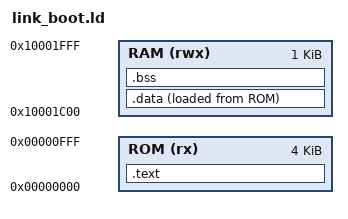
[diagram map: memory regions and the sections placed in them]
/* Linker script bootloader (skenario B): kode di ROM, data dan stack di
 * 1 KB teratas RAM agar 7 KB pertama RAM bebas untuk program yang diunggah. */

OUTPUT_ARCH(riscv)
ENTRY(_start)

MEMORY
{
    ROM (rx)  : ORIGIN = 0x00000000, LENGTH = 4K
    RAM (rwx) : ORIGIN = 0x10001C00, LENGTH = 1K
}

SECTIONS
{
    .text : {
        KEEP(*(.text.start))
        *(.text .text.*)
        *(.rodata .rodata.* .srodata .srodata.*)
        . = ALIGN(4);
    } > ROM

    .data : {
        __data_start = .;
        *(.data .data.* .sdata .sdata.*)
        . = ALIGN(4);
        __data_end = .;
    } > RAM AT > ROM
    __data_load = LOADADDR(.data);

    .bss (NOLOAD) : {
        __bss_start = .;
        *(.bss .bss.* .sbss .sbss.* COMMON)
        . = ALIGN(4);
        __bss_end = .;
    } > RAM

    __stack_top = ORIGIN(RAM) + LENGTH(RAM);

    /DISCARD/ : { *(.comment) *(.riscv.attributes) *(.note*) *(.eh_frame*) }
}
